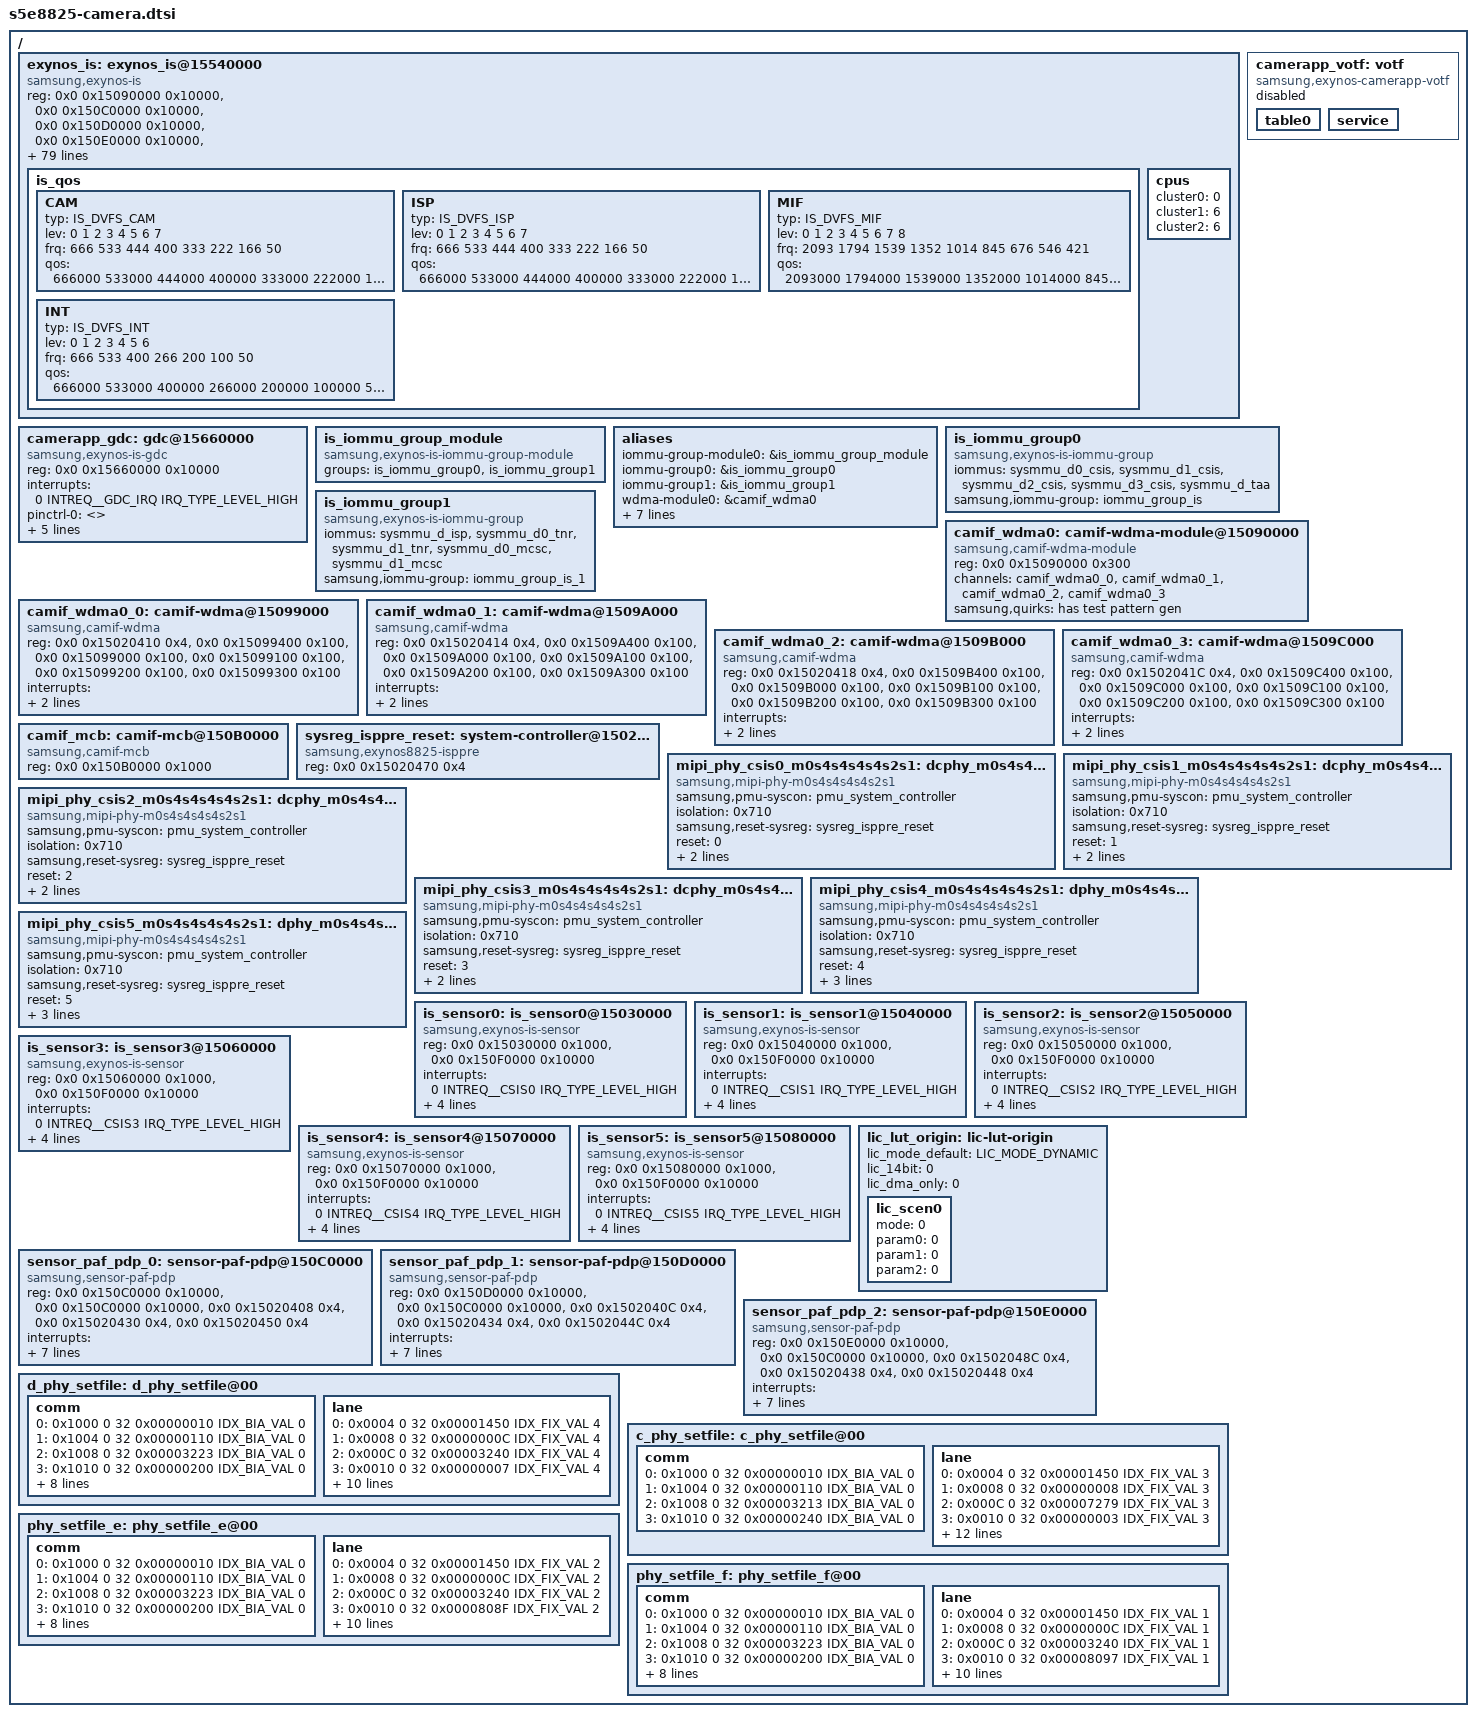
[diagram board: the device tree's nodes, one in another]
/*
 * SAMSUNG EXYNOS8825 SoC camera device tree source
 *
 * Copyright (c) 2021 Samsung Electronics Co., Ltd.
 *		http://www.samsung.com
 *
 * SAMSUNG EXYNOS8825 SoC camera device nodes are listed in this file.
 * EXYNOS8825 based board files can include this file and provide
 * values for board specfic bindings.
 *
 * This program is free software; you can redistribute it and/or modify
 * it under the terms of the GNU General Public License version 2 as
 * published by the Free Software Foundation.
 */

#include <dt-bindings/clock/s5e8825.h>
#include <dt-bindings/interrupt-controller/arm-gic.h>
#include <dt-bindings/interrupt-controller/s5e8825.h>
#include <dt-bindings/camera/exynos_is_dt.h>
#include <dt-bindings/camera/votf.h>
#include "s5e8825-pinctrl.dtsi"

/ {
	exynos_is: exynos_is@15540000 {
		compatible = "samsung,exynos-is";
		reg = <0x0 0x15090000 0x10000>, /* CSIS WDMA */
			<0x0 0x150C0000 0x10000>, /* PDP CORE0 */
			<0x0 0x150D0000 0x10000>, /* PDP CORE1 */
			<0x0 0x150E0000 0x10000>, /* PDP CORE2 */
			<0x0 0x15540000 0x10000>, /* TAA0 */
			<0x0 0x15550000 0x10000>, /* TAA1 */
			<0x0 0x15560000 0x10000>, /* TAA2 */
			<0x0 0x15091000 0x1000>, /* ZSL0 DMA  */
			<0x0 0x15092000 0x1000>, /* ZSL1 DMA  */
			<0x0 0x15093000 0x1000>, /* ZSL2 DMA  */
			<0x0 0x15095000 0x1000>, /* STRP0 DMA  */
			<0x0 0x15096000 0x1000>, /* STRP1 DMA  */
			<0x0 0x15097000 0x1000>, /* STRP2 DMA  */
			<0x0 0x15750000 0x10000>, /* ORBMCH */
			<0x0 0x15440000 0x10000>, /* ITP */
			<0x0 0x14B00000 0x10000>, /* TNR(MCFP0) */
			<0x0 0x14B40000 0x10000>, /* TNR(MCFP1) */
			<0x0 0x15430000 0x10000>, /* DNS */
			<0x0 0x15640000 0x10000>; /* MCSC */
		interrupts = <0 INTREQ__TAA_CH0_0 IRQ_TYPE_LEVEL_HIGH>, /*TAA0_0 */
			   <0 INTREQ__TAA_CH0_1 IRQ_TYPE_LEVEL_HIGH>,   /* TAA0_1 */
			   <0 INTREQ__ZSL_DMA0 IRQ_TYPE_LEVEL_HIGH>,    /* ZSL_DMA_0 */
			   <0 INTREQ__STRP_DMA0 IRQ_TYPE_LEVEL_HIGH>,    /* STRP_DMA_0 */

			   <0 INTREQ__TAA_CH1_0 IRQ_TYPE_LEVEL_HIGH>, /*TAA1_0 */
			   <0 INTREQ__TAA_CH1_1 IRQ_TYPE_LEVEL_HIGH>,   /* TAA1_1 */
			   <0 INTREQ__ZSL_DMA1 IRQ_TYPE_LEVEL_HIGH>,    /* ZSL_DMA_1 */
			   <0 INTREQ__STRP_DMA1 IRQ_TYPE_LEVEL_HIGH>,    /* STRP_DMA_1 */

			   <0 INTREQ__TAA_CH2_0 IRQ_TYPE_LEVEL_HIGH>, /*TAA2_0 */
			   <0 INTREQ__TAA_CH2_1 IRQ_TYPE_LEVEL_HIGH>,   /* TAA2_1 */
			   <0 INTREQ__ZSL_DMA2 IRQ_TYPE_LEVEL_HIGH>,    /* ZSL_DMA_2 */
			   <0 INTREQ__STRP_DMA2 IRQ_TYPE_LEVEL_HIGH>,    /* STRP_DMA_2 */

			   <0 INTREQ__ORBMCH_O_INT IRQ_TYPE_LEVEL_HIGH>, /* ORBMCH */

			   <0 INTREQ__ISP_0 IRQ_TYPE_LEVEL_HIGH>,    /* ITP_0 */
			   <0 INTREQ__ISP_1 IRQ_TYPE_LEVEL_HIGH>,    /* ITP_1 */
			   <0 INTREQ__TNR_0 IRQ_TYPE_LEVEL_HIGH>,     /* TNR_0 */
			   <0 INTREQ__TNR_1 IRQ_TYPE_LEVEL_HIGH>,     /* TNR_1 */
			   <0 INTREQ__MCSC_IRQ IRQ_TYPE_LEVEL_HIGH>;   /* MCSC_0 */
		pinctrl-names = "default","release";
		pinctrl-0 = <>;
		pinctrl-1 = <>;
		clocks = <&clock GATE_DFTMUX_TOP_QCH_CIS_CLK0>,
		      <&clock GATE_DFTMUX_TOP_QCH_CIS_CLK1>,
		      <&clock GATE_DFTMUX_TOP_QCH_CIS_CLK2>,
		      <&clock GATE_DFTMUX_TOP_QCH_CIS_CLK3>,
		      <&clock GATE_DFTMUX_TOP_QCH_CIS_CLK4>,
		      <&clock GATE_DFTMUX_TOP_QCH_CIS_CLK5>,

		      <&clock DOUT_CLKCMU_CIS_CLK0>,
		      <&clock DOUT_CLKCMU_CIS_CLK1>,
		      <&clock DOUT_CLKCMU_CIS_CLK2>,
		      <&clock DOUT_CLKCMU_CIS_CLK3>,
		      <&clock DOUT_CLKCMU_CIS_CLK4>,
		      <&clock DOUT_CLKCMU_CIS_CLK5>,

		      <&clock GATE_CSIS_PDP_QCH_DMA>,

		      <&clock GATE_MIPI_DCPHY_LINK_WRAP_QCH_CSIS0>,
		      <&clock GATE_MIPI_DCPHY_LINK_WRAP_QCH_CSIS1>,
		      <&clock GATE_MIPI_DCPHY_LINK_WRAP_QCH_CSIS2>,
		      <&clock GATE_MIPI_DCPHY_LINK_WRAP_QCH_CSIS3>,
		      <&clock GATE_MIPI_DCPHY_LINK_WRAP_QCH_CSIS4>,
		      <&clock GATE_MIPI_DCPHY_LINK_WRAP_QCH_CSIS5>,

		      <&clock GATE_CSIS_PDP_QCH_PDP_TOP>,
			  <&clock GATE_CSIS_PDP_QCH_MCB>,
		      <&clock GATE_SIPU_TAA_QCH>,
		      <&clock GATE_ORBMCH_QCH_ACLK>,
			  <&clock GATE_TNR_QCH_MCFP0>,
			  <&clock GATE_TNR_QCH_MCFP1>,
		      <&clock GATE_ITP_DNS_QCH_S00>,
		      <&clock GATE_ITP_DNS_QCH_S01>,
		      <&clock GATE_MCSC_QCH>,
		      <&clock GATE_GDC_QCH>;
		clock-names = "GATE_DFTMUX_TOP_QCH_CIS_CLK0",
			"GATE_DFTMUX_TOP_QCH_CIS_CLK1",
			"GATE_DFTMUX_TOP_QCH_CIS_CLK2",
			"GATE_DFTMUX_TOP_QCH_CIS_CLK3",
			"GATE_DFTMUX_TOP_QCH_CIS_CLK4",
			"GATE_DFTMUX_TOP_QCH_CIS_CLK5",

			"DOUT_CLKCMU_CIS_CLK0",
			"DOUT_CLKCMU_CIS_CLK1",
			"DOUT_CLKCMU_CIS_CLK2",
			"DOUT_CLKCMU_CIS_CLK3",
			"DOUT_CLKCMU_CIS_CLK4",
			"DOUT_CLKCMU_CIS_CLK5",

			"GATE_CSIS_PDP_QCH_DMA",

			"GATE_MIPI_DCPHY_LINK_WRAP_QCH_CSIS0",
			"GATE_MIPI_DCPHY_LINK_WRAP_QCH_CSIS1",
			"GATE_MIPI_DCPHY_LINK_WRAP_QCH_CSIS2",
			"GATE_MIPI_DCPHY_LINK_WRAP_QCH_CSIS3",
			"GATE_MIPI_DCPHY_LINK_WRAP_QCH_CSIS4",
			"GATE_MIPI_DCPHY_LINK_WRAP_QCH_CSIS5",

			"GATE_CSIS_PDP_QCH_PDP_TOP",
			"GATE_CSIS_PDP_QCH_MCB",
			"GATE_SIPU_TAA_QCH",
			"GATE_ORBMCH_QCH_ACLK",
			"GATE_TNR_QCH_MCFP0",
			"GATE_TNR_QCH_MCFP1",
			"GATE_ITP_DNS_QCH_S00",
			"GATE_ITP_DNS_QCH_S01",
			"GATE_MCSC_QCH",
			"GATE_GDC_QCH";
		status = "ok";
		iommus = <&sysmmu_d0_csis>,
			 <&sysmmu_d1_csis>,
			 <&sysmmu_d2_csis>,
			 <&sysmmu_d3_csis>,
			 <&sysmmu_d_taa>;
		samsung,iommu-group = <&iommu_group_is>;
		#cooling-cells = <2>; /* min followed by max */
		/* ewf-index = <EWF_GRP_CAM>; */
		list-scen-bts = "camera_default", "camera_heavy";
		num_of_3aa = <3>;
		num_of_lme = <0>;
		num_of_orbmch = <1>;
		num_of_isp = <1>;
		num_of_mcsc = <1>;
		num_of_vra = <0>;
		num_of_clh = <0>;
		num_of_ypp = <0>;

		memory-region = <&camera_rmem>;
		memlog_size = <0x100000 0x100000>;	/* IS_MEMLOG_PRINTF_DRV_SIZE, IS_MEMLOG_PRINTF_DDK_SIZE */

		phy_ldos = "vdd_ldo17", "vdd_ldo14";

		is_qos {
			CAM { /* CSIS, PDP, 3AA */
				typ = <IS_DVFS_CAM>;
				lev = <0      1      2      3      4      5      6      7>;
				frq = <666    533    444    400    333    222    166    50>;
				qos = <666000 533000 444000 400000 333000 222000 166000 50000>;
			};

			ISP { /* TNR, ISP, MCSC, GDC */
				typ = <IS_DVFS_ISP>;
				lev = <0      1      2      3      4      5      6      7>;
				frq = <666    533    444    400    333    222    166    50>;
				qos = <666000 533000 444000 400000 333000 222000 166000 50000>;
			};

			MIF {
				typ = <IS_DVFS_MIF>;
				lev = <0       1       2       3       4       5      6      7      8>;
				frq = <2093    1794    1539    1352    1014    845    676    546    421>;
				qos = <2093000 1794000 1539000 1352000 1014000 845000 676000 546000 421000>;
			};

			INT {
				typ = <IS_DVFS_INT>;
				lev = <0      1      2      3      4      5      6>;
				frq = <666    533    400    266    200    100    50>;
				qos = <666000 533000 400000 266000 200000 100000 50000>;
			};
		};

		cpus {
			cluster0 = <0>;
			cluster1 = <6>;
			cluster2 = <6>;
		};
	};

	camerapp_gdc: gdc@15660000 {
		compatible = "samsung,exynos-is-gdc";
		reg = <0x0 0x15660000 0x10000>; /* GDC */
		interrupts = <0 INTREQ__GDC_IRQ IRQ_TYPE_LEVEL_HIGH>; /* GDC */
		pinctrl-names = "default","release";
		pinctrl-0 = <>;
		pinctrl-1 = <>;
		clocks = <&clock GATE_GDC_QCH>;
		clock-names = "gate";
		status = "okay";
		iommus = <&sysmmu_d0_mcsc>;
		samsung,iommu-group = <&iommu_group_is_1>;
		#cooling-cells = <2>; /* min followed by max */
		dma-coherent;
	};

	camerapp_votf: votf {
		compatible = "samsung,exynos-camerapp-votf";
		status = "disabled";

		table0{
		};

		service {
		};
	};

	is_iommu_group_module: is_iommu_group_module {
		compatible = "samsung,exynos-is-iommu-group-module";
		groups = <&is_iommu_group0>,
			 <&is_iommu_group1>;
	};

	aliases {
		iommu-group-module0 = &is_iommu_group_module;
	};

	is_iommu_group0: is_iommu_group0 {
		compatible = "samsung,exynos-is-iommu-group";
		iommus = <&sysmmu_d0_csis>,
			 <&sysmmu_d1_csis>,
			 <&sysmmu_d2_csis>,
			 <&sysmmu_d3_csis>,
			 <&sysmmu_d_taa>;
		samsung,iommu-group = <&iommu_group_is>;
	};

	is_iommu_group1: is_iommu_group1 {
		compatible = "samsung,exynos-is-iommu-group";
		iommus = <&sysmmu_d_isp>,
			 <&sysmmu_d0_tnr>,
			 <&sysmmu_d1_tnr>,
			 <&sysmmu_d0_mcsc>,
			 <&sysmmu_d1_mcsc>;
		samsung,iommu-group = <&iommu_group_is_1>;
	};

	aliases {
		iommu-group0 = &is_iommu_group0;
		iommu-group1 = &is_iommu_group1;
	};

	camif_wdma0: camif-wdma-module@15090000 {
		compatible = "samsung,camif-wdma-module";
		reg = <0x0 0x15090000 0x300>;
		reg-names = "ctl";
		channels = <&camif_wdma0_0>,
			<&camif_wdma0_1>,
			<&camif_wdma0_2>,
			<&camif_wdma0_3>;
		samsung,quirks = "has test pattern gen";
	};

	aliases {
		wdma-module0 = &camif_wdma0;
	};

	camif_wdma0_0: camif-wdma@15099000 {
		compatible = "samsung,camif-wdma";
		reg = <0x0 0x15020410 0x4>,	/* input MUX */
			<0x0 0x15099400 0x100>,	/* CTL */
			<0x0 0x15099000 0x100>,	/* VC0 */
			<0x0 0x15099100 0x100>,	/* VC1 */
			<0x0 0x15099200 0x100>,	/* VC2 */
			<0x0 0x15099300 0x100>;	/* VC3 */
		reg-names = "mux", "ctl", "vc0", "vc1", "vc2", "vc3";
		interrupts = <GIC_SPI INTREQ__CSIS_DMA0 IRQ_TYPE_LEVEL_HIGH>;
		interrupt-names = "dma";
		module = <&camif_wdma0>;
	};

	camif_wdma0_1: camif-wdma@1509A000 {
		compatible = "samsung,camif-wdma";
		reg = <0x0 0x15020414 0x4>,	/* input MUX */
			<0x0 0x1509A400 0x100>,	/* CTL */
			<0x0 0x1509A000 0x100>,	/* VC0 */
			<0x0 0x1509A100 0x100>,	/* VC1 */
			<0x0 0x1509A200 0x100>,	/* VC2 */
			<0x0 0x1509A300 0x100>;	/* VC3 */
		reg-names = "mux", "ctl", "vc0", "vc1", "vc2", "vc3";
		interrupts = <GIC_SPI INTREQ__CSIS_DMA1 IRQ_TYPE_LEVEL_HIGH>;
		interrupt-names = "dma";
		module = <&camif_wdma0>;
	};

	camif_wdma0_2: camif-wdma@1509B000 {
		compatible = "samsung,camif-wdma";
		reg = <0x0 0x15020418 0x4>,	/* input MUX */
			<0x0 0x1509B400 0x100>,	/* CTL */
			<0x0 0x1509B000 0x100>,	/* VC0 */
			<0x0 0x1509B100 0x100>,	/* VC1 */
			<0x0 0x1509B200 0x100>,	/* VC2 */
			<0x0 0x1509B300 0x100>;	/* VC3 */
		reg-names = "mux", "ctl", "vc0", "vc1", "vc2", "vc3";
		interrupts = <GIC_SPI INTREQ__CSIS_DMA2 IRQ_TYPE_LEVEL_HIGH>;
		interrupt-names = "dma";
		module = <&camif_wdma0>;
	};

	camif_wdma0_3: camif-wdma@1509C000 {
		compatible = "samsung,camif-wdma";
		reg = <0x0 0x1502041C 0x4>,	/* input MUX */
			<0x0 0x1509C400 0x100>,	/* CTL */
			<0x0 0x1509C000 0x100>,	/* VC0 */
			<0x0 0x1509C100 0x100>,	/* VC1 */
			<0x0 0x1509C200 0x100>,	/* VC2 */
			<0x0 0x1509C300 0x100>;	/* VC3 */
		reg-names = "mux", "ctl", "vc0", "vc1", "vc2", "vc3";
		interrupts = <GIC_SPI INTREQ__CSIS_DMA3 IRQ_TYPE_LEVEL_HIGH>;
		interrupt-names = "dma";
		module = <&camif_wdma0>;
	};

	aliases {
		wdma0 = &camif_wdma0_0;
		wdma1 = &camif_wdma0_1;
		wdma2 = &camif_wdma0_2;
		wdma3 = &camif_wdma0_3;
	};

	camif_mcb: camif-mcb@150B0000 {
		compatible = "samsung,camif-mcb";
		reg = <0x0 0x150B0000 0x1000>;
	};

	sysreg_isppre_reset: system-controller@15020470 {
		compatible = "samsung,exynos8825-isppre", "syscon";
		reg = <0x0 0x15020470 0x4>;
	};

	mipi_phy_csis0_m0s4s4s4s4s2s1: dcphy_m0s4s4s4s4s2s1_csi0@15020470 {
		/* DPHY 6.5 Gbps 4lane, CPHY 4.5 Gbps 3lane */
		compatible = "samsung,mipi-phy-m0s4s4s4s4s2s1";
		samsung,pmu-syscon = <&pmu_system_controller>;
		isolation = <0x710>; /* PMU address offset */
		samsung,reset-sysreg = <&sysreg_isppre_reset>;
		reset = <0>; /* reset bit */
		reg = <0x0 0x150F1300 0x500>;
		owner = <1>; /* 0: DSI,  1: CSI */
		#phy-cells = <1>;
	};

	mipi_phy_csis1_m0s4s4s4s4s2s1: dcphy_m0s4s4s4s4s2s1_csi1@15020470 {
		/* DPHY 6.5 Gbps 4lane */
		/* CPHY 4.5 Gbps 3lane */
		compatible = "samsung,mipi-phy-m0s4s4s4s4s2s1";
		samsung,pmu-syscon = <&pmu_system_controller>;
		isolation = <0x710>; /* PMU address offset */
		samsung,reset-sysreg = <&sysreg_isppre_reset>;
		reset = <1>; /* reset bit */
		reg = <0x0 0x150F1B00 0x500>;
		owner = <1>; /* 0: DSI,  1: CSI */
		#phy-cells = <1>;
	};

	mipi_phy_csis2_m0s4s4s4s4s2s1: dcphy_m0s4s4s4s4s2s1_csi2@15020470 {
		/* DPHY 6.5 Gbps 4lane */
		compatible = "samsung,mipi-phy-m0s4s4s4s4s2s1";
		samsung,pmu-syscon = <&pmu_system_controller>;
		isolation = <0x710>; /* PMU address offset */
		samsung,reset-sysreg = <&sysreg_isppre_reset>;
		reset = <2>; /* reset bit */
		reg = <0x0 0x150F2300 0x500>;
		owner = <1>; /* 0: DSI,  1: CSI */
		#phy-cells = <1>;
	};

	mipi_phy_csis3_m0s4s4s4s4s2s1: dcphy_m0s4s4s4s4s2s1_csi3@15020470 {
		/* DPHY 6.5 Gbps 4lane */
		compatible = "samsung,mipi-phy-m0s4s4s4s4s2s1";
		samsung,pmu-syscon = <&pmu_system_controller>;
		isolation = <0x710>; /* PMU address offset */
		samsung,reset-sysreg = <&sysreg_isppre_reset>;
		reset = <3>; /* reset bit */
		reg = <0x0 0x150F2B00 0x500>;
		owner = <1>; /* 0: DSI,  1: CSI */
		#phy-cells = <1>;
	};

	mipi_phy_csis4_m0s4s4s4s4s2s1: dphy_m0s4s4s4s4s2s1_csi4@15020470 {
		/* DPHY 6.5 Gbps 2lane */
		compatible = "samsung,mipi-phy-m0s4s4s4s4s2s1";
		samsung,pmu-syscon = <&pmu_system_controller>;
		isolation = <0x710>; /* PMU address offset */
		samsung,reset-sysreg = <&sysreg_isppre_reset>;
		reset = <4>; /* reset bit */
		reg = <0x0 0x150F3300 0x100>, /* clock */
			<0x0 0x150F2E00 0x200>; /* lane */
		reg-names = "clock", "lane";
		owner = <1>; /* 0: DSI,  1: CSI */
		#phy-cells = <1>;
	};

	mipi_phy_csis5_m0s4s4s4s4s2s1: dphy_m0s4s4s4s4s2s1_csi5@15020470 {
		/* DPHY 6.5 Gbps 1lane */
		compatible = "samsung,mipi-phy-m0s4s4s4s4s2s1";
		samsung,pmu-syscon = <&pmu_system_controller>;
		isolation = <0x710>; /* PMU address offset */
		samsung,reset-sysreg = <&sysreg_isppre_reset>;
		reset = <5>; /* reset bit */
		reg = <0x0 0x150F3B00 0x100>, /* clock */
			<0x0 0x150F2F00 0x100>; /* lane */
		reg-names = "clock", "lane";
		owner = <1>; /* 0: DSI,  1: CSI */
		#phy-cells = <1>;
	};

	is_sensor0: is_sensor0@15030000 {
		/* CSIS0 */
		compatible = "samsung,exynos-is-sensor";
		#address-cells = <1>;
		#size-cells = <1>;
		reg = <0x0 0x15030000 0x1000>, /* MIPI-CSI0 */
			<0x0 0x150F0000 0x10000>; /* PHY: M0S4S4S4S4S2S1 */
		reg-names = "csi", "phy";
		interrupts = <0 INTREQ__CSIS0 IRQ_TYPE_LEVEL_HIGH>; /* MIPI-CSI0 */
		interrupt-names = "csi";
		phys = <&mipi_phy_csis0_m0s4s4s4s4s2s1 0>;
		phy-names = "csis_dphy";
		phy_setfile = <&d_phy_setfile>;
		iommus = <&sysmmu_d0_csis>, <&sysmmu_d1_csis>;
		samsung,iommu-group = <&iommu_group_is>;
	};

	is_sensor1: is_sensor1@15040000 {
		/* CSIS1 */
		compatible = "samsung,exynos-is-sensor";
		#address-cells = <1>;
		#size-cells = <1>;
		reg = <0x0 0x15040000 0x1000>, /* MIPI-CSI1 */
			<0x0 0x150F0000 0x10000>; /* PHY: M0S4S4S4S4S2S1 */
		reg-names = "csi", "phy";
		interrupts = <0 INTREQ__CSIS1 IRQ_TYPE_LEVEL_HIGH>; /* MIPI-CSI1 */
		interrupt-names = "csi";
		phys = <&mipi_phy_csis1_m0s4s4s4s4s2s1 0>;
		phy-names = "csis_dphy";
		phy_setfile = <&d_phy_setfile>;
		iommus = <&sysmmu_d0_csis>, <&sysmmu_d1_csis>;
		samsung,iommu-group = <&iommu_group_is>;
	};

	is_sensor2: is_sensor2@15050000 {
		/* CSIS2 */
		compatible = "samsung,exynos-is-sensor";
		#address-cells = <1>;
		#size-cells = <1>;
		reg = <0x0 0x15050000 0x1000>, /* MIPI-CSI2 */
			<0x0 0x150F0000 0x10000>; /* PHY: M0S4S4S4S4S2S1 */
		reg-names = "csi", "phy";
		interrupts = <0 INTREQ__CSIS2 IRQ_TYPE_LEVEL_HIGH>; /* MIPI-CSI2 */
		interrupt-names = "csi";
		phys = <&mipi_phy_csis2_m0s4s4s4s4s2s1 0>;
		phy-names = "csis_dphy";
		phy_setfile = <&d_phy_setfile>;
		iommus = <&sysmmu_d0_csis>, <&sysmmu_d1_csis>;
		samsung,iommu-group = <&iommu_group_is>;
	};

	is_sensor3: is_sensor3@15060000 {
		/* CSIS3 */
		compatible = "samsung,exynos-is-sensor";
		#address-cells = <1>;
		#size-cells = <1>;
		reg = <0x0 0x15060000 0x1000>, /* MIPI-CSI3 */
			<0x0 0x150F0000 0x10000>; /* PHY: M0S4S4S4S4S2S1 */
		reg-names = "csi", "phy";
		interrupts = <0 INTREQ__CSIS3 IRQ_TYPE_LEVEL_HIGH>; /* MIPI-CSI3 */
		interrupt-names = "csi";
		phys = <&mipi_phy_csis3_m0s4s4s4s4s2s1 0>;
		phy-names = "csis_dphy";
		phy_setfile = <&d_phy_setfile>;
		iommus = <&sysmmu_d0_csis>, <&sysmmu_d1_csis>;
		samsung,iommu-group = <&iommu_group_is>;
	};

	is_sensor4: is_sensor4@15070000 {
		/* CSIS4 */
		compatible = "samsung,exynos-is-sensor";
		#address-cells = <1>;
		#size-cells = <1>;
		reg = <0x0 0x15070000 0x1000>, /* MIPI-CSI4 */
			<0x0 0x150F0000 0x10000>; /* PHY: M0S4S4S4S4S2S1 */
		reg-names = "csi", "phy";
		interrupts = <0 INTREQ__CSIS4 IRQ_TYPE_LEVEL_HIGH>; /* MIPI-CSI4 */
		interrupt-names = "csi";
		phys = <&mipi_phy_csis4_m0s4s4s4s4s2s1 0>;
		phy-names = "csis_dphy";
		phy_setfile = <&phy_setfile_e>;	/* 2+2 lane */
		iommus = <&sysmmu_d0_csis>, <&sysmmu_d1_csis>;
		samsung,iommu-group = <&iommu_group_is>;
	};

	is_sensor5: is_sensor5@15080000 {
		/* CSIS5 */
		compatible = "samsung,exynos-is-sensor";
		#address-cells = <1>;
		#size-cells = <1>;
		reg = <0x0 0x15080000 0x1000>, /* MIPI-CSI5 */
			<0x0 0x150F0000 0x10000>; /* PHY: M0S4S4S4S4S2S1 */
		reg-names = "csi", "phy";
		interrupts = <0 INTREQ__CSIS5 IRQ_TYPE_LEVEL_HIGH>; /* MIPI-CSI5 */
		interrupt-names = "csi";
		phys = <&mipi_phy_csis5_m0s4s4s4s4s2s1 0>;
		phy-names = "csis_dphy";
		phy_setfile = <&phy_setfile_f>;	/* 2+1+1 lane */
		iommus = <&sysmmu_d0_csis>, <&sysmmu_d1_csis>;
		samsung,iommu-group = <&iommu_group_is>;
	};

	lic_lut_origin: lic-lut-origin {
		#define LIC_MODE_DYNAMIC	(0)
		#define LIC_MODE_STATIC		(1)
		#define LIC_PATH_OTF		(0)
		#define LIC_PATH_DMA		(1)

		lic_mode_default = <LIC_MODE_DYNAMIC>;
		lic_14bit = <0>;
		lic_dma_only = <0>; /* Use this when NOT using OTF input at all. */

		/*
		 * When DYNAMIC mode is selected, param means enable limitation for DMA path.
		 * Example:
		 * @ mode = <LIC_MODE_DYNAMIC>;
		 * @ param0 = <LIC_PATH_OTF>;
		 * @ param1 = <LIC_PATH_DMA>;
		 * @ param2 = <LIC_PATH_OTF>;
		 *
		 * When STATIC mode is selected, param means buffer size for each context.
		 * Example:
		 * @ mode = <LIC_MODE_STAIC>;
		 * @ param0 = <3584>;
		 * @ param1 = <3583>;
		 * @ param2 = <1>;
		 *
		 * The lic_scen0 is not abailable. If the index of LUT is "0", the selection is skipped.
		 */
		lic_scen0 { /* Reserved */
			mode = <0>;
			param0 = <0>;
			param1 = <0>;
			param2 = <0>;
		};
	};

	sensor_paf_pdp_0: sensor-paf-pdp@150C0000 {
		/* PDP CORE0 */
		compatible = "samsung,sensor-paf-pdp";
		reg = <0x0 0x150C0000 0x10000>, /* PDP CORE0 */
			<0x0 0x150C0000 0x10000>, /* PDP CORE0: For common regiser */
			<0x0 0x15020408 0x4>, /* PDP input mux(CSIS_PDP_SC_CON0) in SYSREG */
			<0x0 0x15020430 0x4>, /* PDP input vc mux(CSIS_PDP_VC_CON0) in SYSREG */
			<0x0 0x15020450 0x4>; /* CSIS_PDP_SC_PDP0_IN_EN in SYSREG */
		reg-names = "core", "common", "mux", "vc_mux", "en";
		interrupts = <0 INTREQ__PDP_TOP0 IRQ_TYPE_LEVEL_HIGH>,
			<0 INTREQ__PDP_TOP1 IRQ_TYPE_LEVEL_HIGH>;
		mux =  <0 1 2 3 4 5>; /* <csi0 csi1 csi2 csi3 csi4 csi5> */
		vc_mux = <0x1 0x1 0x1 0x1 0x1 0x1>; /* <csi0 csi1 csi2 csi3 csi4 csi5> */
		en =  <0 1 2 3 4 5>; /* bit postion: <csi0 csi1 csi2 csi3 csi4 csi5> */
		leader; /* have RDMA & create video node */
		lic_lut = <&lic_lut_origin>;
	};

	sensor_paf_pdp_1: sensor-paf-pdp@150D0000 {
		/* PDP CORE0 */
		compatible = "samsung,sensor-paf-pdp";
		reg = <0x0 0x150D0000 0x10000>, /* PDP CORE0 */
			<0x0 0x150C0000 0x10000>, /* PDP CORE0: For common regiser */
			<0x0 0x1502040C 0x4>, /* PDP input mux(CSIS_PDP_SC_CON1) in SYSREG */
			<0x0 0x15020434 0x4>, /* PDP input vc mux(CSIS_PDP_VC_CON1) in SYSREG */
			<0x0 0x1502044C 0x4>; /* CSIS_PDP_SC_PDP1_IN_EN in SYSREG */
		reg-names = "core", "common", "mux", "vc_mux", "en";
		interrupts = <0 INTREQ__PDP_TOP2 IRQ_TYPE_LEVEL_HIGH>,
			<0 INTREQ__PDP_TOP3 IRQ_TYPE_LEVEL_HIGH>;
		mux =  <0 1 2 3 4 5>; /* <csi0 csi1 csi2 csi3 csi4 csi5> */
		vc_mux = <0x1 0x1 0x1 0x1 0x1 0x1>; /* <csi0 csi1 csi2 csi3 csi4 csi5> */
		en =  <0 1 2 3 4 5>; /* bit postion: <csi0 csi1 csi2 csi3 csi4 csi5> */
		leader; /* have RDMA & create video node */
		lic_lut = <&lic_lut_origin>;
	};

	sensor_paf_pdp_2: sensor-paf-pdp@150E0000 {
		/* PDP CORE0 */
		compatible = "samsung,sensor-paf-pdp";
		reg = <0x0 0x150E0000 0x10000>, /* PDP CORE0 */
			<0x0 0x150C0000 0x10000>, /* PDP CORE0: For common regiser */
			<0x0 0x1502048C 0x4>, /* PDP input mux(CSIS_PDP_SC_CON2) in SYSREG */
			<0x0 0x15020438 0x4>, /* PDP input vc mux(CSIS_PDP_VC_CON2) in SYSREG */
			<0x0 0x15020448 0x4>; /* CSIS_PDP_SC_PDP2_IN_EN in SYSREG */
		reg-names = "core", "common", "mux", "vc_mux", "en";
		interrupts = <0 INTREQ__PDP_TOP4 IRQ_TYPE_LEVEL_HIGH>,
			<0 INTREQ__PDP_TOP5 IRQ_TYPE_LEVEL_HIGH>;
		mux =  <0 1 2 3 4 5>; /* <csi0 csi1 csi2 csi3 csi4 csi5> */
		vc_mux = <0x1 0x1 0x1 0x1 0x1 0x1>; /* <csi0 csi1 csi2 csi3 csi4 csi5> */
		en =  <0 1 2 3 4 5>; /* bit postion: <csi0 csi1 csi2 csi3 csi4 csi5> */
		leader; /* have RDMA & create video node */
		lic_lut = <&lic_lut_origin>;
	};

	aliases {
		pdp0 = &sensor_paf_pdp_0;
		pdp1 = &sensor_paf_pdp_1;
		pdp2 = &sensor_paf_pdp_2;
	};

	/*
	 * phy setfile
	 * <addr, bit_start, bit_width, val, index, max_lane>
	 */
	d_phy_setfile: d_phy_setfile@00 {
		comm {
			/* bias */
			0  = <0x1000 0 32 0x00000010 IDX_BIA_VAL 0>; /* M_BIAS_CON0 */
			1  = <0x1004 0 32 0x00000110 IDX_BIA_VAL 0>; /* M_BIAS_CON1 */
			2  = <0x1008 0 32 0x00003223 IDX_BIA_VAL 0>; /* M_BIAS_CON2 */
			3  = <0x1010 0 32 0x00000200 IDX_BIA_VAL 0>; /* M_BIAS_CON4 */

			/* clock */
			4 = <0x0004 0 32 0x00001450 IDX_FIX_VAL 0>; /* SC_GNR_CON1 */
			5 = <0x0008 0 32 0x00000009 IDX_FIX_VAL 0>; /* SC_ANA_CON0 */
			6 = <0x000C 0 32 0x0000EA40 IDX_FIX_VAL 0>; /* SC_ANA_CON1 */
			7 = <0x0010 0 32 0x00000002 IDX_FIX_VAL 0>; /* SC_ANA_CON2 */
			8 = <0x0014 0 32 0x00008600 IDX_FIX_VAL 0>; /* SC_ANA_CON3 */
			9 = <0x0018 0 32 0x00004000 IDX_FIX_VAL 0>; /* SC_ANA_CON4 */
			10 = <0x0030 0 32 0x00000301 IDX_FIX_VAL 0>; /* SC_TIME_CON0 */
			/* Enable should be set at last. */
			11 = <0x0000 0 32 0x00000001 IDX_FIX_VAL 0>; /* SC_GNR_CON0, Phy clock enable */
		};

		lane {
			0  = <0x0004 0 32 0x00001450 IDX_FIX_VAL 4>; /* SD_GNR_CON1 */
			1  = <0x0008 0 32 0x0000000C IDX_FIX_VAL 4>; /* SD_ANA_CON0 */
			2  = <0x000C 0 32 0x00003240 IDX_FIX_VAL 4>; /* SD_ANA_CON1 */
			3  = <0x0010 0 32 0x00000007 IDX_FIX_VAL 4>; /* SD_ANA_CON2 */
			4  = <0x0010 8  2 0x00000000 IDX_SKW_DLY 4>; /* SD_ANA_CON2 */
			5  = <0x0014 0 32 0x00008600 IDX_FIX_VAL 4>; /* SD_ANA_CON3 */
			6  = <0x0018 0 32 0x00004000 IDX_FIX_VAL 4>; /* SD_ANA_CON4 */
			7  = <0x0024 0 32 0x00000040 IDX_FIX_VAL 4>; /* SD_ANA_CON7 */
			8  = <0x0030 0  8 0x00000000 IDX_STL_VAL 4>; /* SD_TIME_CON0 */
			9  = <0x0030 8  1 0x00000000 IDX_STL_CLK 4>; /* SD_TIME_CON0 */
			10 = <0x0034 0 32 0x00000003 IDX_FIX_VAL 4>; /* SD_TIME_CON1 */
			11 = <0x0040 0  1 0x00000001 IDX_SKW_CAL 4>; /* SD_DESKEW_CON0 */
			12 = <0x0050 0 32 0x0000081A IDX_FIX_VAL 4>; /* SD_DESKEW_CON4 */
			/* Enable should be set at last. */
			13 = <0x0000 0 32 0x00000001 IDX_FIX_VAL 4>; /* SD_GNR_CON0 , Phy data enable */
		};
	};

	c_phy_setfile: c_phy_setfile@00 {
		comm {
			/* bias */
			0  = <0x1000 0 32 0x00000010 IDX_BIA_VAL 0>; /* M_BIAS_CON0 */
			1  = <0x1004 0 32 0x00000110 IDX_BIA_VAL 0>; /* M_BIAS_CON1 */
			2  = <0x1008 0 32 0x00003213 IDX_BIA_VAL 0>; /* M_BIAS_CON2 */
			3  = <0x1010 0 32 0x00000240 IDX_BIA_VAL 0>; /* M_BIAS_CON4 */
		};

		lane {
			0  = <0x0004 0 32 0x00001450 IDX_FIX_VAL 3>; /* SD_GNR_CON1 */
			1  = <0x0008 0 32 0x00000008 IDX_FIX_VAL 3>; /* SD_ANA_CON0 */
			2  = <0x000C 0 32 0x00007279 IDX_FIX_VAL 3>; /* SD_ANA_CON1 */
			3  = <0x0010 0 32 0x00000003 IDX_FIX_VAL 3>; /* SD_ANA_CON2 */
			4  = <0x0014 0 32 0x00008600 IDX_FIX_VAL 3>; /* SD_ANA_CON3 */
			5  = <0x0018 0 32 0x00004000 IDX_FIX_VAL 3>; /* SD_ANA_CON4 */
			6  = <0x001c 0 32 0x00000200 IDX_FIX_VAL 3>; /* SD_ANA_CON5 */
			7  = <0x0020 0 32 0x00000608 IDX_FIX_VAL 3>; /* SD_ANA_CON6 */
			8  = <0x0024 0 32 0x00000040 IDX_FIX_VAL 3>; /* SD_ANA_CON7 */
			9  = <0x0030 0  8 0x00000000 IDX_STL_VAL 3>; /* SD_TIME_CON0 */
			10 = <0x0030 8  1 0x00000000 IDX_STL_CLK 3>; /* SD_TIME_CON0 */
			11 = <0x0034 0 32 0x00000032 IDX_FIX_VAL 3>; /* SD_TIME_CON1 */
			12 = <0x0040 0  1 0x00000000 IDX_SKW_CAL 3>; /* SD_DESKEW_CON0 */
			13 = <0x0064 0 32 0x00001502 IDX_FIX_VAL 3>; /* SD_CRC_CON1 */
			14 = <0x0068 0 32 0x00000003 IDX_FIX_VAL 3>; /* SD_CRC_CON2 */
			/* Enable should be set at last. */
			15 = <0x0000 0 32 0x00000001 IDX_FIX_VAL 3>; /* SD_GNR_CON0 , Phy data enable */
		};
	};

	/*
	 * 2+2 lane
	 */
	phy_setfile_e: phy_setfile_e@00 {
		comm {
			/* bias */
			0  = <0x1000 0 32 0x00000010 IDX_BIA_VAL 0>; /* M_BIAS_CON0 */
			1  = <0x1004 0 32 0x00000110 IDX_BIA_VAL 0>; /* M_BIAS_CON1 */
			2  = <0x1008 0 32 0x00003223 IDX_BIA_VAL 0>; /* M_BIAS_CON2 */
			3  = <0x1010 0 32 0x00000200 IDX_BIA_VAL 0>; /* M_BIAS_CON4 */

			/* clock */
			4 = <0x0004 0 32 0x00001450 IDX_FIX_VAL 0>; /* SC_GNR_CON1 */
			5 = <0x0008 0 32 0x00000009 IDX_FIX_VAL 0>; /* SC_ANA_CON0 */
			6 = <0x000C 0 32 0x0000EA40 IDX_FIX_VAL 0>; /* SC_ANA_CON1 */
			7 = <0x0010 0 32 0x00000002 IDX_FIX_VAL 0>; /* SC_ANA_CON2 */
			8 = <0x0014 0 32 0x00008600 IDX_FIX_VAL 0>; /* SC_ANA_CON3 */
			9 = <0x0018 0 32 0x00004000 IDX_FIX_VAL 0>; /* SC_ANA_CON4 */
			10 = <0x0030 0 32 0x00000301 IDX_FIX_VAL 0>; /* SC_TIME_CON0 */
			/* Enable should be set at last. */
			11 = <0x0000 0 32 0x00000001 IDX_FIX_VAL 0>; /* SC_GNR_CON0, Phy clock enable */
		};

		lane {
			0  = <0x0004 0 32 0x00001450 IDX_FIX_VAL 2>; /* SD_GNR_CON1 */
			1  = <0x0008 0 32 0x0000000C IDX_FIX_VAL 2>; /* SD_ANA_CON0 */
			2  = <0x000C 0 32 0x00003240 IDX_FIX_VAL 2>; /* SD_ANA_CON1 */
			3  = <0x0010 0 32 0x0000808F IDX_FIX_VAL 2>; /* SD_ANA_CON2 */
			4  = <0x0010 8  2 0x00000000 IDX_SKW_DLY 2>; /* SD_ANA_CON2 */
			5  = <0x0014 0 32 0x00008600 IDX_FIX_VAL 2>; /* SD_ANA_CON3 */
			6  = <0x0018 0 32 0x00004000 IDX_FIX_VAL 2>; /* SD_ANA_CON4 */
			7  = <0x0024 0 32 0x00000040 IDX_FIX_VAL 2>; /* SD_ANA_CON7 */
			8  = <0x0030 0  8 0x00000000 IDX_STL_VAL 2>; /* SD_TIME_CON0 */
			9  = <0x0030 8  1 0x00000000 IDX_STL_CLK 2>; /* SD_TIME_CON0 */
			10 = <0x0034 0 32 0x00000003 IDX_FIX_VAL 2>; /* SD_TIME_CON1 */
			11 = <0x0040 0  1 0x00000001 IDX_SKW_CAL 2>; /* SD_DESKEW_CON0 */
			12 = <0x0050 0 32 0x0000081A IDX_FIX_VAL 2>; /* SD_DESKEW_CON4 */
			/* Enable should be set at last. */
			13 = <0x0000 0 32 0x00000001 IDX_FIX_VAL 2>; /* SD_GNR_CON0 , Phy data enable */
		};
	};

	/*
	 * 2+1+1 lane
	 */
	phy_setfile_f: phy_setfile_f@00 {
		comm {
			/* bias */
			0  = <0x1000 0 32 0x00000010 IDX_BIA_VAL 0>; /* M_BIAS_CON0 */
			1  = <0x1004 0 32 0x00000110 IDX_BIA_VAL 0>; /* M_BIAS_CON1 */
			2  = <0x1008 0 32 0x00003223 IDX_BIA_VAL 0>; /* M_BIAS_CON2 */
			3  = <0x1010 0 32 0x00000200 IDX_BIA_VAL 0>; /* M_BIAS_CON4 */

			/* clock */
			4 = <0x0004 0 32 0x00001450 IDX_FIX_VAL 0>; /* SC_GNR_CON1 */
			5 = <0x0008 0 32 0x00000009 IDX_FIX_VAL 0>; /* SC_ANA_CON0 */
			6 = <0x000C 0 32 0x0000EA40 IDX_FIX_VAL 0>; /* SC_ANA_CON1 */
			7 = <0x0010 0 32 0x00000002 IDX_FIX_VAL 0>; /* SC_ANA_CON2 */
			8 = <0x0014 0 32 0x00008600 IDX_FIX_VAL 0>; /* SC_ANA_CON3 */
			9 = <0x0018 0 32 0x00004000 IDX_FIX_VAL 0>; /* SC_ANA_CON4 */
			10 = <0x0030 0 32 0x00000301 IDX_FIX_VAL 0>; /* SC_TIME_CON0 */
			/* Enable should be set at last. */
			11 = <0x0000 0 32 0x00000001 IDX_FIX_VAL 0>; /* SC_GNR_CON0, Phy clock enable */
		};

		lane {
			0  = <0x0004 0 32 0x00001450 IDX_FIX_VAL 1>; /* SD_GNR_CON1 */
			1  = <0x0008 0 32 0x0000000C IDX_FIX_VAL 1>; /* SD_ANA_CON0 */
			2  = <0x000C 0 32 0x00003240 IDX_FIX_VAL 1>; /* SD_ANA_CON1 */
			3  = <0x0010 0 32 0x00008097 IDX_FIX_VAL 1>; /* SD_ANA_CON2 */
			4  = <0x0010 8  2 0x00000000 IDX_SKW_DLY 1>; /* SD_ANA_CON2 */
			5  = <0x0014 0 32 0x00008600 IDX_FIX_VAL 1>; /* SD_ANA_CON3 */
			6  = <0x0018 0 32 0x00004000 IDX_FIX_VAL 1>; /* SD_ANA_CON4 */
			7  = <0x0024 0 32 0x00000040 IDX_FIX_VAL 1>; /* SD_ANA_CON7 */
			8  = <0x0030 0  8 0x00000000 IDX_STL_VAL 1>; /* SD_TIME_CON0 */
			9  = <0x0030 8  1 0x00000000 IDX_STL_CLK 1>; /* SD_TIME_CON0 */
			10 = <0x0034 0 32 0x00000003 IDX_FIX_VAL 1>; /* SD_TIME_CON1 */
			11 = <0x0040 0  1 0x00000001 IDX_SKW_CAL 1>; /* SD_DESKEW_CON0 */
			12 = <0x0050 0 32 0x0000081A IDX_FIX_VAL 1>; /* SD_DESKEW_CON4 */
			/* Enable should be set at last. */
			13 = <0x0000 0 32 0x00000001 IDX_FIX_VAL 1>; /* SD_GNR_CON0 , Phy data enable */
		};
	};
};
